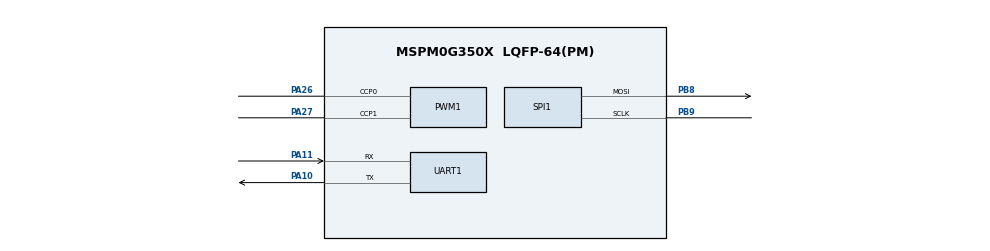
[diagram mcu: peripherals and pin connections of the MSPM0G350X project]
/**
 * @cliArgs --device "MSPM0G350X" --part "Default" --package "LQFP-64(PM)" --product "mspm0_sdk@2.02.00.05"
 * @versions {"tool":"1.21.1+3772"}
 */

/**
 * Import the modules used in this configuration.
 */
const ADC12  = scripting.addModule("/ti/driverlib/ADC12", {}, false);
const ADC121 = ADC12.addInstance();
const DMA    = scripting.addModule("/ti/driverlib/DMA");
const GPIO   = scripting.addModule("/ti/driverlib/GPIO", {}, false);
const GPIO1  = GPIO.addInstance();
const GPIO2  = GPIO.addInstance();
const GPIO3  = GPIO.addInstance();
const GPIO4  = GPIO.addInstance();
const GPIO5  = GPIO.addInstance();
const PWM    = scripting.addModule("/ti/driverlib/PWM", {}, false);
const PWM1   = PWM.addInstance();
const SPI    = scripting.addModule("/ti/driverlib/SPI", {}, false);
const SPI1   = SPI.addInstance();
const SYSCTL = scripting.addModule("/ti/driverlib/SYSCTL");
const TIMER  = scripting.addModule("/ti/driverlib/TIMER", {}, false);
const TIMER1 = TIMER.addInstance();
const UART   = scripting.addModule("/ti/driverlib/UART", {}, false);
const UART1  = UART.addInstance();

/**
 * Write custom configuration values to the imported modules.
 */
const divider9       = system.clockTree["UDIV"];
divider9.divideValue = 2;

const multiplier2         = system.clockTree["PLL_QDIV"];
multiplier2.multiplyValue = 4;

const mux4       = system.clockTree["EXHFMUX"];
mux4.inputSelect = "EXHFMUX_XTAL";

const mux8       = system.clockTree["HSCLKMUX"];
mux8.inputSelect = "HSCLKMUX_SYSPLL0";

const mux12       = system.clockTree["SYSPLLMUX"];
mux12.inputSelect = "zSYSPLLMUX_HFCLK";

const pinFunction4        = system.clockTree["HFXT"];
pinFunction4.enable       = true;
pinFunction4.inputFreq    = 40;
pinFunction4.HFCLKMonitor = true;
pinFunction4.HFXTStartup  = 10;

ADC121.sampClkDiv                        = "DL_ADC12_CLOCK_DIVIDE_8";
ADC121.$name                             = "ADC_STICK_Y";
ADC121.repeatMode                        = true;
ADC121.adcMem0_name                      = "CH0";
ADC121.powerDownMode                     = "DL_ADC12_POWER_DOWN_MODE_MANUAL";
ADC121.sampleTime0                       = "10 ms";
ADC121.enabledInterrupts                 = ["DL_ADC12_INTERRUPT_MEM0_RESULT_LOADED"];
ADC121.peripheral.$assign                = "ADC1";
ADC121.peripheral.adcPin0.$assign        = "PA15";
ADC121.adcPin0Config.hideOutputInversion = scripting.forceWrite(false);
ADC121.adcPin0Config.$name               = "ti_driverlib_gpio_GPIOPinGeneric6";

const Board = scripting.addModule("/ti/driverlib/Board", {}, false);

GPIO1.$name                              = "DEBUG_LED";
GPIO1.associatedPins[0].$name            = "PIN_22";
GPIO1.associatedPins[0].assignedPort     = "PORTB";
GPIO1.associatedPins[0].assignedPin      = "22";
GPIO1.associatedPins[0].internalResistor = "PULL_DOWN";

GPIO2.$name                          = "GPIO_LCD";
GPIO2.associatedPins.create(4);
GPIO2.associatedPins[0].$name        = "PIN_RES";
GPIO2.associatedPins[0].assignedPort = "PORTB";
GPIO2.associatedPins[0].assignedPin  = "10";
GPIO2.associatedPins[1].$name        = "PIN_DC";
GPIO2.associatedPins[1].assignedPort = "PORTB";
GPIO2.associatedPins[1].assignedPin  = "11";
GPIO2.associatedPins[2].$name        = "PIN_CS";
GPIO2.associatedPins[2].assignedPort = "PORTB";
GPIO2.associatedPins[2].assignedPin  = "14";
GPIO2.associatedPins[3].$name        = "PIN_BLK";
GPIO2.associatedPins[3].assignedPort = "PORTB";
GPIO2.associatedPins[3].assignedPin  = "26";

GPIO3.$name                              = "GPIO_KEY";
GPIO3.associatedPins.create(5);
GPIO3.associatedPins[0].$name            = "PIN_UP";
GPIO3.associatedPins[0].direction        = "INPUT";
GPIO3.associatedPins[0].internalResistor = "PULL_UP";
GPIO3.associatedPins[0].assignedPort     = "PORTA";
GPIO3.associatedPins[0].assignedPin      = "9";
GPIO3.associatedPins[1].$name            = "PIN_LEFT";
GPIO3.associatedPins[1].direction        = "INPUT";
GPIO3.associatedPins[1].internalResistor = "PULL_UP";
GPIO3.associatedPins[1].assignedPort     = "PORTA";
GPIO3.associatedPins[1].assignedPin      = "8";
GPIO3.associatedPins[2].$name            = "PIN_RIGHT";
GPIO3.associatedPins[2].direction        = "INPUT";
GPIO3.associatedPins[2].internalResistor = "PULL_UP";
GPIO3.associatedPins[2].assignedPort     = "PORTA";
GPIO3.associatedPins[2].assignedPin      = "31";
GPIO3.associatedPins[3].$name            = "PIN_DOWN";
GPIO3.associatedPins[3].direction        = "INPUT";
GPIO3.associatedPins[3].internalResistor = "PULL_UP";
GPIO3.associatedPins[3].assignedPort     = "PORTA";
GPIO3.associatedPins[3].assignedPin      = "28";
GPIO3.associatedPins[4].$name            = "PIN_MID";
GPIO3.associatedPins[4].direction        = "INPUT";
GPIO3.associatedPins[4].internalResistor = "PULL_UP";
GPIO3.associatedPins[4].assignedPort     = "PORTB";
GPIO3.associatedPins[4].assignedPin      = "4";

GPIO4.$name                               = "GPIO_ENCODER";
GPIO4.associatedPins.create(2);
GPIO4.associatedPins[0].$name             = "PIN_A";
GPIO4.associatedPins[0].direction         = "INPUT";
GPIO4.associatedPins[0].assignedPort      = "PORTB";
GPIO4.associatedPins[0].assignedPin       = "0";
GPIO4.associatedPins[0].interruptEn       = true;
GPIO4.associatedPins[0].polarity          = "RISE";
GPIO4.associatedPins[0].interruptPriority = "0";
GPIO4.associatedPins[1].$name             = "PIN_B";
GPIO4.associatedPins[1].direction         = "INPUT";
GPIO4.associatedPins[1].assignedPort      = "PORTB";
GPIO4.associatedPins[1].assignedPin       = "1";
GPIO4.associatedPins[1].interruptEn       = true;
GPIO4.associatedPins[1].polarity          = "RISE";
GPIO4.associatedPins[1].interruptPriority = "0";

GPIO5.$name                              = "GPIO_STICK_Z";
GPIO5.port                               = "PORTA";
GPIO5.associatedPins[0].internalResistor = "PULL_UP";
GPIO5.associatedPins[0].direction        = "INPUT";
GPIO5.associatedPins[0].$name            = "SWITCH";
GPIO5.associatedPins[0].assignedPin      = "22";

PWM1.$name                              = "PWM_MOTOR";
PWM1.timerStartTimer                    = true;
PWM1.timerCount                         = 10000;
PWM1.peripheral.$assign                 = "TIMG7";
PWM1.peripheral.ccp0Pin.$assign         = "PA26";
PWM1.peripheral.ccp1Pin.$assign         = "PA27";
PWM1.PWM_CHANNEL_0.$name                = "ti_driverlib_pwm_PWMTimerCC0";
PWM1.PWM_CHANNEL_1.$name                = "ti_driverlib_pwm_PWMTimerCC1";
PWM1.ccp0PinConfig.direction            = scripting.forceWrite("OUTPUT");
PWM1.ccp0PinConfig.hideOutputInversion  = scripting.forceWrite(false);
PWM1.ccp0PinConfig.onlyInternalResistor = scripting.forceWrite(false);
PWM1.ccp0PinConfig.passedPeripheralType = scripting.forceWrite("Digital");
PWM1.ccp0PinConfig.$name                = "ti_driverlib_gpio_GPIOPinGeneric4";
PWM1.ccp1PinConfig.direction            = scripting.forceWrite("OUTPUT");
PWM1.ccp1PinConfig.hideOutputInversion  = scripting.forceWrite(false);
PWM1.ccp1PinConfig.onlyInternalResistor = scripting.forceWrite(false);
PWM1.ccp1PinConfig.passedPeripheralType = scripting.forceWrite("Digital");
PWM1.ccp1PinConfig.$name                = "ti_driverlib_gpio_GPIOPinGeneric5";

SPI1.$name                              = "SPI_LCD";
SPI1.targetBitRate                      = 32000000;
SPI1.frameFormat                        = "MOTO3";
SPI1.direction                          = "PICO";
SPI1.peripheral.$assign                 = "SPI1";
SPI1.peripheral.sclkPin.$assign         = "PB9";
SPI1.peripheral.mosiPin.$assign         = "PB8";
SPI1.sclkPinConfig.direction            = scripting.forceWrite("OUTPUT");
SPI1.sclkPinConfig.onlyInternalResistor = scripting.forceWrite(false);
SPI1.sclkPinConfig.passedPeripheralType = scripting.forceWrite("Digital");
SPI1.sclkPinConfig.$name                = "ti_driverlib_gpio_GPIOPinGeneric2";
SPI1.mosiPinConfig.direction            = scripting.forceWrite("OUTPUT");
SPI1.mosiPinConfig.hideOutputInversion  = scripting.forceWrite(false);
SPI1.mosiPinConfig.onlyInternalResistor = scripting.forceWrite(false);
SPI1.mosiPinConfig.passedPeripheralType = scripting.forceWrite("Digital");
SPI1.mosiPinConfig.$name                = "ti_driverlib_gpio_GPIOPinGeneric3";

SYSCTL.forceDefaultClkConfig = true;
SYSCTL.clockTreeEn           = true;

TIMER1.$name             = "TIMER_TICK";
TIMER1.timerClkDiv       = 8;
TIMER1.timerClkPrescale  = 10;
TIMER1.timerPeriod       = "20 ms";
TIMER1.timerStartTimer   = true;
TIMER1.interruptPriority = "3";
TIMER1.interrupts        = ["ZERO"];
TIMER1.timerMode         = "PERIODIC";

UART1.$name                            = "UART_DEBUG";
UART1.enabledInterrupts                = ["RX"];
UART1.interruptPriority                = "3";
UART1.peripheral.rxPin.$assign         = "PA11";
UART1.peripheral.txPin.$assign         = "PA10";
UART1.txPinConfig.direction            = scripting.forceWrite("OUTPUT");
UART1.txPinConfig.hideOutputInversion  = scripting.forceWrite(false);
UART1.txPinConfig.onlyInternalResistor = scripting.forceWrite(false);
UART1.txPinConfig.passedPeripheralType = scripting.forceWrite("Digital");
UART1.txPinConfig.$name                = "ti_driverlib_gpio_GPIOPinGeneric0";
UART1.rxPinConfig.hideOutputInversion  = scripting.forceWrite(false);
UART1.rxPinConfig.onlyInternalResistor = scripting.forceWrite(false);
UART1.rxPinConfig.passedPeripheralType = scripting.forceWrite("Digital");
UART1.rxPinConfig.$name                = "ti_driverlib_gpio_GPIOPinGeneric1";

/**
 * Pinmux solution for unlocked pins/peripherals. This ensures that minor changes to the automatic solver in a future
 * version of the tool will not impact the pinmux you originally saw.  These lines can be completely deleted in order to
 * re-solve from scratch.
 */
pinFunction4.peripheral.$suggestSolution           = "SYSCTL";
pinFunction4.peripheral.hfxInPin.$suggestSolution  = "PA5";
pinFunction4.peripheral.hfxOutPin.$suggestSolution = "PA6";
Board.peripheral.$suggestSolution                  = "DEBUGSS";
Board.peripheral.swclkPin.$suggestSolution         = "PA20";
Board.peripheral.swdioPin.$suggestSolution         = "PA19";
GPIO1.associatedPins[0].pin.$suggestSolution       = "PB22";
GPIO2.associatedPins[0].pin.$suggestSolution       = "PB10";
GPIO2.associatedPins[1].pin.$suggestSolution       = "PB11";
GPIO2.associatedPins[2].pin.$suggestSolution       = "PB14";
GPIO2.associatedPins[3].pin.$suggestSolution       = "PB26";
GPIO3.associatedPins[0].pin.$suggestSolution       = "PA9";
GPIO3.associatedPins[1].pin.$suggestSolution       = "PA8";
GPIO3.associatedPins[2].pin.$suggestSolution       = "PA31";
GPIO3.associatedPins[3].pin.$suggestSolution       = "PA28";
GPIO3.associatedPins[4].pin.$suggestSolution       = "PB4";
GPIO4.associatedPins[0].pin.$suggestSolution       = "PB0";
GPIO4.associatedPins[1].pin.$suggestSolution       = "PB1";
GPIO5.associatedPins[0].pin.$suggestSolution       = "PA22";
TIMER1.peripheral.$suggestSolution                 = "TIMA0";
UART1.peripheral.$suggestSolution                  = "UART0";
